# S6E2CCxJ register map
Vendor: Cypress; File version: 2.1
CPU: CM4 r0p1, little endian, MPU, FPU, 4 interrupt priority bits
Registers are 32-bit, read-write, reset 0x0 unless marked. A register's access mark holds for its fields unless they carry their own. Offsets are from the block's base; [hi:lo] are bit positions; {n}, {i} and the like mark numbered series; 'fields as' and 'values as' point back to an identical list.

## LSCRP — Low-speed CR Prescaler
Base 0x4003C000
0x00 LCR_PRSLD 8-bit — Low-speed CR Prescaler Control Register [BHW]
  [5:0] LCR_PRSLD — Low-speed CR Prescaler Load

## I2SPRE — I2S Clock Generation
Base 0x4003D000
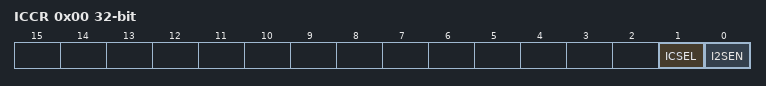
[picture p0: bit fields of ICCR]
0x00 ICCR — I2S Clock Control Register [BHW]
  [1] ICSEL — I2S clock selection bit
  [0] I2SEN — I2S clock output enable bit
0x04 IPCR1 — I2S-PLL Control Register 1 [BHW]
  [0] IPLLEN — I2S-PLL oscillation enable bit
0x08 IPCR2 — I2S-PLL Control Register 2 [BHW]
  [2:0] IPOWT — I2S-PLL oscillation stabilization wait time setting bits
0x0C IPCR3 reset 0x1 — I2S-PLL Control Register 3 [BHW]
  [4:0] IPLLK — Frequency division ratio (K) setting bits of the I2S-PLL clock
0x10 IPCR4 reset 0x1F — I2S-PLL Control Register 4 [BHW]
  [6:0] IPLLN — Frequency division ratio (N) setting bits of the I2S-PLL clock
0x14 IP_STR ro — I2S-PLL Status Register [BHW]
  [0] IPRDY — I2S-PLL oscillation stabilization bit
0x18 IPINT_ENR — I2S-PLL Interrupt Factor Enable Register [BHW]
  [0] IPCSE — I2S-PLL oscillation stabilization wait complete interrupt enable bit
0x1C IPINT_CLR wo — I2S-PLL Interrupt Factor Status Register [BHW]
  [0] IPCSC — I2S-PLL interrupt factor status bit
0x20 IPINT_STR ro — I2S-PLL Interrupt Factor Clear Register [BHW]
  [0] IPCSI — I2S-PLL oscillation stabilization interrupt factor clear bit
0x24 IPCR5 reset 0x18 — I2S-PLL Control Register 5 [BHW]
  [6:0] IPLLM — Frequency division ratio (M) setting bits of the I2S-PLL clock

## DMAC — DMAC Registers
Base 0x40060000
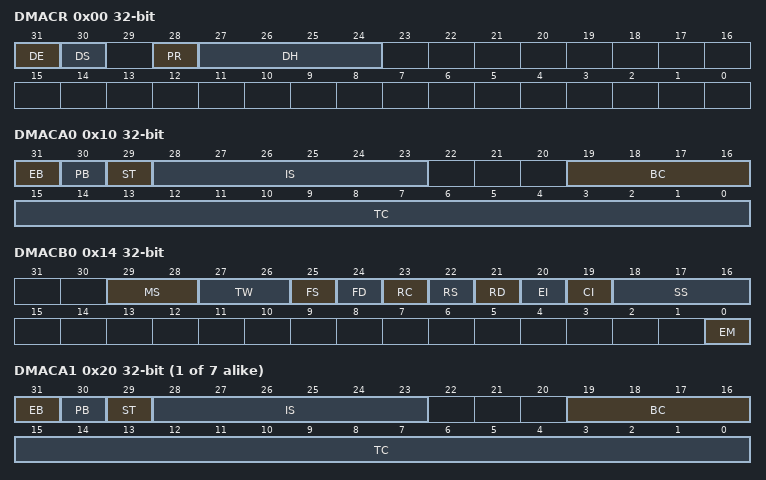
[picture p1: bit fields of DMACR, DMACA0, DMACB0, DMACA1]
0x00 DMACR — Entire DMAC Configuration Register [BHW]
  [31] DE — DMA Enable (all-channel operation enable bit)
  [30] DS — DMA Stop
  [28] PR — Priority Rotation
  [27:24] DH — DMA Halt (All-channel pause bit)
0x10 DMACA0 — Configuration A Register [BHW]
  [31] EB — Enable bit (individual-channel operation enable bit)
  [30] PB — Pause bit (individual-channel pause bit)
  [29] ST — Software Trigger
  [28:23] IS — Input Select
  [19:16] BC — Block Count
  [15:0] TC — Transfer Count
0x14 DMACB0 — Configuration B Register [BHW]
  [29:28] MS — Mode Select
  [27:26] TW — Transfer Width
  [25] FS — Fixed Source
  [24] FD — Fixed Destination
  [23] RC — Reload Count (BC/TC reload)
  [22] RS — Reload Source
  [21] RD — Reload Destination
  [20] EI — Error Interrupt (unsuccessful transfer completion interrupt enable)
  [19] CI — Completion Interrupt (successful transfer completion interrupt enable)
  [18:16] SS — Stop Status (stop status notification)
  [0] EM — Enable bit Mask (EB bit clear mask)
{0x18+0x10*i} DMACSA{i} (i=0..7) — Transfer Source Address Register {i} [BHW]
{0x1C+0x10*i} DMACDA{i} (i=0..7) — Transfer Destination Address Register {i} [BHW]
{0x10+0x10*i} DMACA{i} (i=1..7) — Configuration A Register {i} [BHW]
  fields as DMACA0
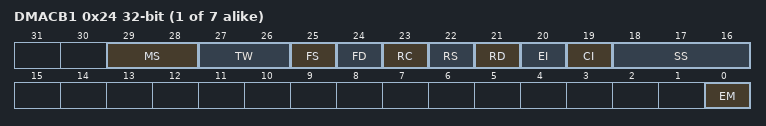
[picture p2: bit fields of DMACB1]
{0x14+0x10*i} DMACB{i} (i=1..7) — Configuration B Register {i} [BHW]
  fields as DMACB0

## DSTC — DSTC registers
Base 0x40061000
0x00 DESTP — Descriptor top address Register [BHW]
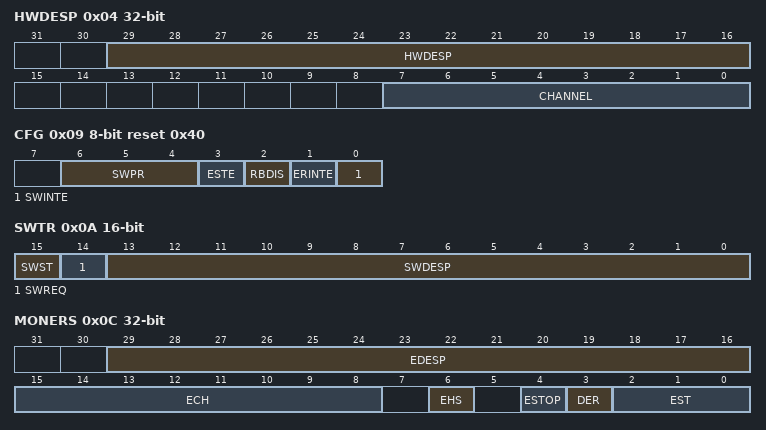
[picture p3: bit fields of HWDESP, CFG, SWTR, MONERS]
0x04 HWDESP — Hardware DES pointer Register [BHW]
  [29:16] HWDESP, [7:0] CHANNEL
0x08 CMD 8-bit reset 0x1 — Command Register [B]
0x09 CFG 8-bit reset 0x40 — Configuration Register [B]
  [6:4] SWPR — Software transfer priority
  [3] ESTE — Error stop enable
  [2] RBDIS — Read skip buffer disable
  [1] ERINTE — Error interrupt enable
  [0] SWINTE — Software interrupt enable
0x0A SWTR 16-bit — Software trigger Register [H]
  [15] SWST ro — Software status
  [14] SWREQ ro — Software request
  [13:0] SWDESP — Software DES pointer
0x0C MONERS ro — Transfer Error Status Monitor Register [BHW]
  [29:16] EDESP — Error DES pointer
  [15:8] ECH — Error hardware channel
  [6] EHS — Error hardware software
  [4] ESTOP — Error stop
  [3] DER — Double error
  [2:0] EST — Error status
{0x10+4i} DREQENB{i} (i=0..7) — DMA request enable Register {i} [BHW]
{0x30+4i} HWINT{i} ro (i=0..7) — Hardware transfer interrupt Register {i} [BHW]
{0x50+4i} HWINTCLR{i} wo (i=0..7) — Hardware transfer interrupt clear Register {i} [BHW]
{0x70+4i} DQMSK{i} ro (i=0..7) — DMA request mask Register {i} [BHW]
{0x90+4i} DQMSKCLR{i} wo (i=0..7) — DMA request mask clear Register {i} [BHW]

## ETHERNET_CONTROL — Ethernet system control
Base 0x40066000
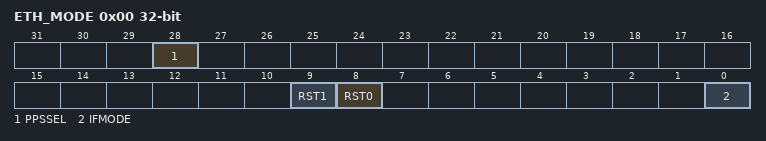
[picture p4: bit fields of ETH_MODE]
0x00 ETH_MODE — Mode Select Register [BHW]
  [28] PPSSEL — Select either of the system time counter pulse outputs of the Ethernet-MAC PTP function to output to E_PPS0_PPS1 pin
  [9] RST1 — reset signal against Ethernet-MAC (ch.1)
  [8] RST0 — reset signal against Ethernet-MAC (ch.0)
  [0] IFMODE — Mode selector
0x08 ETH_CLKG — Clock Gating Register [BHW]
  [1:0] MACEN — Select the system clock supply to Ethernet-MAC

## PCRC — 0
Base 0x40080000
0x00 PCRC_POLY reset 0x4C11DB7 — CRC Computing Generator Polynomial Register [BHW]
0x04 PCRC_SEED reset 0xFFFFFFFF — CRC Computing Initial Value Register [BHW]
0x08 PCRC_FXOR reset 0xFFFFFFFF — CRC Computing Resault XOR Value Register [BHW]
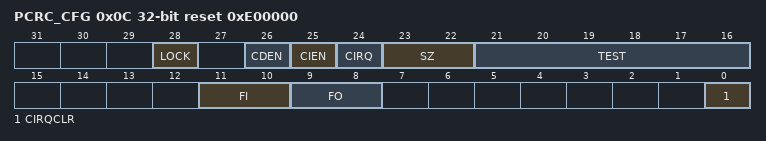
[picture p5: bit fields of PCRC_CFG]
0x0C PCRC_CFG reset 0xE00000 — CRC Computing Configuration Register [BHW]
  [28] LOCK ro
  [26] CDEN — DMA request enable
  [25] CIEN — Interrupt request enable
  [24] CIRQ ro — Interrupt request
  [23:22] SZ — Input data size
  [21:16] TEST
  [11:10] FI — Input data format
  [9:8] FO — output data format
  [0] CIRQCLR wo — Interrupt request clear
0x10 PCRC_WR — CRC Computing Input Data Register [BHW]
0x14 PCRC_RD — CRC Computing Output Data Register [BHW]

## Notices in the file
Copyright (C) 2013-2016, Cypress Semiconductor Corporation or a
subsidiary of Cypress Semiconductor Corporation.  All rights reserved.
This software, including source code, documentation and related
materials ("Software"), is owned by Cypress Semiconductor Corporation or
one of its subsidiaries ("Cypress") and is protected by and subject to
worldwide patent protection (United States and foreign), United States
copyright laws and international treaty provisions. Therefore, you may use
this Software only as provided in the license agreement accompanying the
software package from which you obtained this Software ("EULA").
If no EULA applies, Cypress hereby grants you a personal, non-exclusive,
non-transferable license to copy, modify, and compile the
Software source code solely for use in connection with Cypress's
integrated circuit products.  Any reproduction, modification, translation,
compilation, or representation of this Software except as specified
above is prohibited without the express written permission of Cypress.
Disclaimer: THIS SOFTWARE IS PROVIDED AS-IS, WITH NO
WARRANTY OF ANY KIND, EXPRESS OR IMPLIED, INCLUDING,
BUT NOT LIMITED TO, NONINFRINGEMENT, IMPLIED
WARRANTIES OF MERCHANTABILITY AND FITNESS FOR A
PARTICULAR PURPOSE. Cypress reserves the right to make
changes to the Software without notice. Cypress does not assume any
liability arising out of the application or use of the Software or any
product or circuit described in the Software. Cypress does not
authorize its products for use in any products where a malfunction or
failure of the Cypress product may reasonably be expected to result in
significant property damage, injury or death ("High Risk Product"). By
including Cypress's product in a High Risk Product, the manufacturer
of such system or application assumes all risk of such use and in doing
so agrees to indemnify Cypress against all liability.
